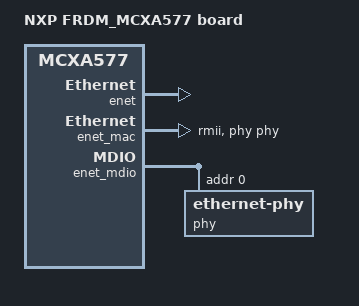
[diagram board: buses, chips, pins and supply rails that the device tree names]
/*
 * Copyright 2025-2026 NXP
 *
 * SPDX-License-Identifier: Apache-2.0
 */

/dts-v1/;

#include <nxp/mcx/nxp_mcxa5x.dtsi>
#include "frdm_mcxa577.dtsi"

/ {
	model = "NXP FRDM_MCXA577 board";
	compatible = "nxp,mcxa577", "nxp,mcx";

	chosen {
		zephyr,sram = &sram0;
		zephyr,flash = &flash;
		zephyr,flash-controller = &fmu;
		zephyr,code-partition = &slot0_partition;
		zephyr,console = &lpuart1;
		zephyr,shell-uart = &lpuart1;
	};
};

&enet {
	status = "okay";
	pinctrl-0 = <&pinmux_enet_qos>;
	pinctrl-names = "default";
};

&enet_mac {
	status = "okay";
	phy-connection-type = "rmii";
	zephyr,random-mac-address;
	phy-handle = <&phy>;
};

&enet_mdio {
	status = "okay";

	phy: ethernet-phy@0 {
		compatible = "ethernet-phy";
		reg = <0>;
		status = "okay";
	};
};
